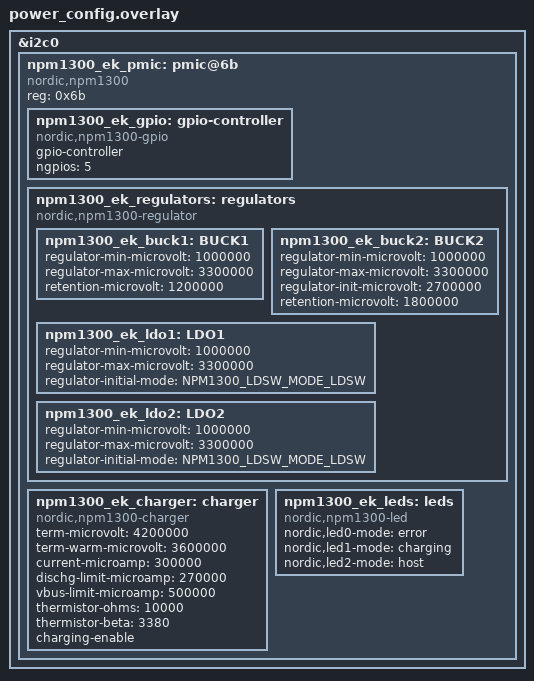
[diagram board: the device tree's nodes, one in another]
/*
* Copyright (C) 2023 Nordic Semiconductor ASA
* SPDX-License-Identifier: Apache-2.0
*/

#include <dt-bindings/regulator/npm1300.h>
#include <zephyr/dt-bindings/input/input-event-codes.h>

&i2c0 {
   npm1300_ek_pmic: pmic@6b {
       compatible = "nordic,npm1300";
       reg = <0x6b>;

       
    // ship-to-active-time = <96>;

       
    // long-press-reset = "one_button";


       npm1300_ek_gpio: gpio-controller {
           compatible = "nordic,npm1300-gpio";
           gpio-controller;
           #gpio-cells = <2>;
           ngpios = <5>;
       };

       npm1300_ek_regulators: regulators {
           compatible = "nordic,npm1300-regulator";

           
npm1300_ek_buck1: BUCK1 {
    regulator-min-microvolt = <1000000>;
    regulator-max-microvolt = <3300000>;
    
    retention-microvolt = <1200000>;
    
    
    
    
    
};



npm1300_ek_buck2: BUCK2 {
    regulator-min-microvolt = <1000000>;
    regulator-max-microvolt = <3300000>;
    regulator-init-microvolt =  <2700000>;
    retention-microvolt = <1800000>;
    
    
    
    
    
};


            
npm1300_ek_ldo1: LDO1 {
    regulator-min-microvolt = <1000000>;
    regulator-max-microvolt = <3300000>;
    
    regulator-initial-mode = <NPM1300_LDSW_MODE_LDSW>;
    
    
};



npm1300_ek_ldo2: LDO2 {
    regulator-min-microvolt = <1000000>;
    regulator-max-microvolt = <3300000>;
    
    regulator-initial-mode = <NPM1300_LDSW_MODE_LDSW>;
    
    
};

       };

       
npm1300_ek_charger: charger {
    compatible = "nordic,npm1300-charger";
    term-microvolt = <4200000>;
    term-warm-microvolt = <3600000>;
    // term-current-percent = <10>;
    current-microamp = <300000>;
    // trickle-microvolt = <2900000>;
    dischg-limit-microamp = <270000>;
    vbus-limit-microamp = <500000>;
    thermistor-ohms = <10000>;
    thermistor-beta = <3380>;
    
    charging-enable;
    
};

       
npm1300_ek_leds: leds {
    compatible = "nordic,npm1300-led";
    nordic,led0-mode = "error";    
nordic,led1-mode = "charging";    
nordic,led2-mode = "host";
};

   };
};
